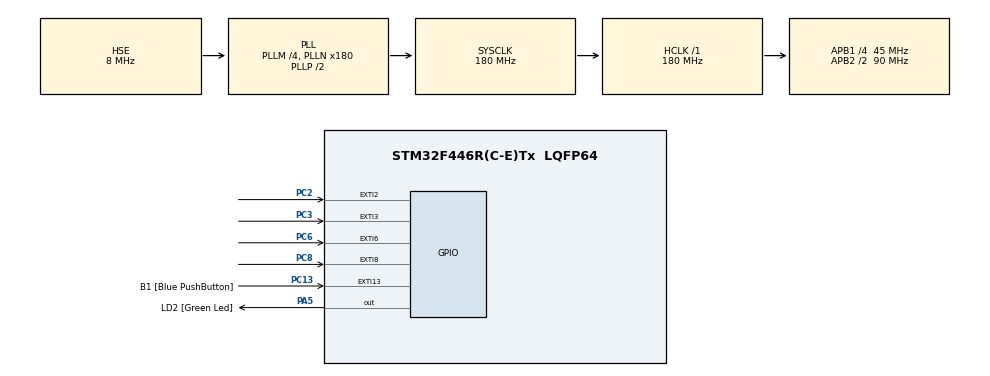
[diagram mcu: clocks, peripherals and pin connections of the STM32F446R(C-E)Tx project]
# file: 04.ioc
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Mcu.Family=STM32F4
Mcu.Name=STM32F446R(C-E)Tx
Mcu.Package=LQFP64
NVIC.EXTI2_IRQn=true\:0\:0\:false\:false\:true
NVIC.EXTI3_IRQn=true\:0\:0\:false\:false\:true
NVIC.EXTI9_5_IRQn=true\:0\:0\:false\:false\:true
NVIC.PriorityGroup=NVIC_PRIORITYGROUP_0
PA13.GPIO_Label=TMS
PA13.Mode=Serial_Wire
PA13.Signal=SYS_JTMS-SWDIO
PA14.GPIO_Label=TCK
PA14.Mode=Serial_Wire
PA14.Signal=SYS_JTCK-SWCLK
PA2.GPIO_Label=USART_TX
PA2.Signal=USART2_TX
PA3.GPIO_Label=USART_RX
PA3.Signal=USART2_RX
PA5.GPIO_Label=LD2 [Green Led]
PA5.Signal=GPIO_Output
PB3.GPIO_Label=SWO
PB3.Signal=SYS_JTDO-SWO
PC13.GPIO_Label=B1 [Blue PushButton]
PC13.GPIO_ModeDefaultEXTI=GPIO_MODE_EVT_RISING
PC13.Signal=GPXTI13
PC14-OSC32_IN.Signal=RCC_OSC32_IN
PC15-OSC32_OUT.Signal=RCC_OSC32_OUT
PC2.Signal=GPXTI2
PC3.GPIO_ModeDefaultEXTI=GPIO_MODE_IT_RISING
PC3.Signal=GPXTI3
PC6.Signal=GPXTI6
PC8.Signal=GPXTI8
PH0-OSC_IN.Mode=HSE-External-Clock-Source
PH0-OSC_IN.Signal=RCC_OSC_IN
PH1-OSC_OUT.Mode=HSE-External-Clock-Source
PH1-OSC_OUT.Signal=RCC_OSC_OUT
ProjectManager.HeapSize=0x200
ProjectManager.StackSize=0x400
ProjectManager.TargetToolchain=SW4STM32
RCC.AHBFreq_Value=180000000
RCC.APB1CLKDivider=RCC_HCLK_DIV4
RCC.APB1Freq_Value=45000000
RCC.APB1TimFreq_Value=90000000
RCC.APB2CLKDivider=RCC_HCLK_DIV2
RCC.APB2Freq_Value=90000000
RCC.APB2TimFreq_Value=180000000
RCC.CortexFreq_Value=180000000
RCC.FLatency-AdvancedSettings=FLASH_LATENCY_5
RCC.HCLKFreq_Value=180000000
RCC.HSE_VALUE=8000000
RCC.HSI_VALUE=16000000
RCC.LSE_VALUE=32768
RCC.PLLM=4
RCC.PLLN=180
RCC.PLLSourceVirtual=RCC_PLLSOURCE_HSE
RCC.SYSCLKFreq_VALUE=180000000
RCC.SYSCLKSource=RCC_SYSCLKSOURCE_PLLCLK
RCC.USBFreq_Value=180000000
RCC.VCOOutputFreq_Value=360000000
board=NUCLEO-F446RE

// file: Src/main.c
/**
  ******************************************************************************
  * File Name          : main.c
  * Description        : Main program body
  ******************************************************************************
  *
  * COPYRIGHT(c) 2016 STMicroelectronics
  *
  * Redistribution and use in source and binary forms, with or without modification,
  * are permitted provided that the following conditions are met:
  *   1. Redistributions of source code must retain the above copyright notice,
  *      this list of conditions and the following disclaimer.
  *   2. Redistributions in binary form must reproduce the above copyright notice,
  *      this list of conditions and the following disclaimer in the documentation
  *      and/or other materials provided with the distribution.
  *   3. Neither the name of STMicroelectronics nor the names of its contributors
  *      may be used to endorse or promote products derived from this software
  *      without specific prior written permission.
  *
  * THIS SOFTWARE IS PROVIDED BY THE COPYRIGHT HOLDERS AND CONTRIBUTORS "AS IS"
  * AND ANY EXPRESS OR IMPLIED WARRANTIES, INCLUDING, BUT NOT LIMITED TO, THE
  * IMPLIED WARRANTIES OF MERCHANTABILITY AND FITNESS FOR A PARTICULAR PURPOSE ARE
  * DISCLAIMED. IN NO EVENT SHALL THE COPYRIGHT HOLDER OR CONTRIBUTORS BE LIABLE
  * FOR ANY DIRECT, INDIRECT, INCIDENTAL, SPECIAL, EXEMPLARY, OR CONSEQUENTIAL
  * DAMAGES (INCLUDING, BUT NOT LIMITED TO, PROCUREMENT OF SUBSTITUTE GOODS OR
  * SERVICES; LOSS OF USE, DATA, OR PROFITS; OR BUSINESS INTERRUPTION) HOWEVER
  * CAUSED AND ON ANY THEORY OF LIABILITY, WHETHER IN CONTRACT, STRICT LIABILITY,
  * OR TORT (INCLUDING NEGLIGENCE OR OTHERWISE) ARISING IN ANY WAY OUT OF THE USE
  * OF THIS SOFTWARE, EVEN IF ADVISED OF THE POSSIBILITY OF SUCH DAMAGE.
  *
  ******************************************************************************
  */
#include "main.h"
#include "stm32f4xx_hal.h"
#include "gpio.h"

/* USER CODE BEGIN Includes */
#include "lcd.h"
/* USER CODE END Includes */

/* USER CODE BEGIN PV */
/* Private variables ---------------------------------------------------------*/
volatile uint8_t button = 0;
uint32_t time0 = 0;

/* USER CODE END PV */

void SystemClock_Config(void);
void Error_Handler(void);

/* USER CODE BEGIN PFP */
/* Private function prototypes -----------------------------------------------*/
void prints(int time)
{
	LCD_Printf("Result: %d\n", time-time0);
	time0=time;
}
int checks(int time)
{
	return time-time0;
}
/* USER CODE END PFP */

int main(void)
{

  /* MCU Configuration----------------------------------------------------------*/

  /* Reset of all peripherals, Initializes the Flash interface and the Systick. */
  HAL_Init();

  /* Configure the system clock */
  SystemClock_Config();

  /* Initialize all configured peripherals */
  MX_GPIO_Init();

  /* USER CODE BEGIN 2 */
  LCD_Init();

  /* USER CODE END 2 */

  /* Infinite loop */
  /* USER CODE BEGIN WHILE */
  while (1)
  {
	  uint32_t tick = HAL_GetTick();

//	  if(button !=0)
//	  {
//		  if(button== 3){
//		  	LCD_FillScreen(BLACK);
//		  	LCD_SetCursor(0, 0);
//		  } else {
//		  	LCD_Printf("Button: %d\n", button);
//		  	button = 0;
//		  }
//	  }	else {
//		LCD_Printf("");
//	  }
//	  	HAL_Delay(1000);

	  if(button == 2 && checks(tick)> 200){
		  prints(tick);
		  button=0;
	  }
  /* USER CODE END WHILE */

  }

}

/** System Clock Configuration
*/
void SystemClock_Config(void)
{

  RCC_OscInitTypeDef RCC_OscInitStruct;
  RCC_ClkInitTypeDef RCC_ClkInitStruct;

    /**Configure the main internal regulator output voltage
    */
  __HAL_RCC_PWR_CLK_ENABLE();

  __HAL_PWR_VOLTAGESCALING_CONFIG(PWR_REGULATOR_VOLTAGE_SCALE1);

    /**Initializes the CPU, AHB and APB busses clocks
    */
  RCC_OscInitStruct.OscillatorType = RCC_OSCILLATORTYPE_HSE;
  RCC_OscInitStruct.HSEState = RCC_HSE_BYPASS;
  RCC_OscInitStruct.PLL.PLLState = RCC_PLL_ON;
  RCC_OscInitStruct.PLL.PLLSource = RCC_PLLSOURCE_HSE;
  RCC_OscInitStruct.PLL.PLLM = 4;
  RCC_OscInitStruct.PLL.PLLN = 180;
  RCC_OscInitStruct.PLL.PLLP = RCC_PLLP_DIV2;
  RCC_OscInitStruct.PLL.PLLQ = 2;
  RCC_OscInitStruct.PLL.PLLR = 2;
  if (HAL_RCC_OscConfig(&RCC_OscInitStruct) != HAL_OK)
  {
    Error_Handler();
  }

    /**Activate the Over-Drive mode
    */
  if (HAL_PWREx_EnableOverDrive() != HAL_OK)
  {
    Error_Handler();
  }

    /**Initializes the CPU, AHB and APB busses clocks
    */
  RCC_ClkInitStruct.ClockType = RCC_CLOCKTYPE_HCLK|RCC_CLOCKTYPE_SYSCLK
                              |RCC_CLOCKTYPE_PCLK1|RCC_CLOCKTYPE_PCLK2;
  RCC_ClkInitStruct.SYSCLKSource = RCC_SYSCLKSOURCE_PLLCLK;
  RCC_ClkInitStruct.AHBCLKDivider = RCC_SYSCLK_DIV1;
  RCC_ClkInitStruct.APB1CLKDivider = RCC_HCLK_DIV4;
  RCC_ClkInitStruct.APB2CLKDivider = RCC_HCLK_DIV2;

  if (HAL_RCC_ClockConfig(&RCC_ClkInitStruct, FLASH_LATENCY_5) != HAL_OK)
  {
    Error_Handler();
  }

    /**Configure the Systick interrupt time
    */
  HAL_SYSTICK_Config(HAL_RCC_GetHCLKFreq()/1000);

    /**Configure the Systick
    */
  HAL_SYSTICK_CLKSourceConfig(SYSTICK_CLKSOURCE_HCLK);

  /* SysTick_IRQn interrupt configuration */
  HAL_NVIC_SetPriority(SysTick_IRQn, 0, 0);
}

void Error_Handler(void)
{
  while(1)
  {
  }
}

/************************ (C) COPYRIGHT STMicroelectronics *****END OF FILE****/
